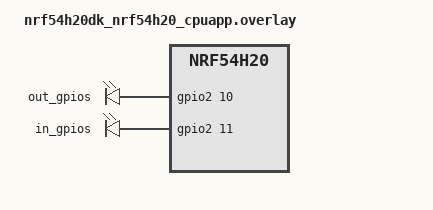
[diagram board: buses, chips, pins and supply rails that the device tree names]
/*
 * Copyright (c) 2025 Nordic Semiconductor ASA
 *
 * SPDX-License-Identifier: LicenseRef-Nordic-5-Clause
 */

/ {
	/* Test requirements:
	 * NFC antenna connected to the DK.
	 */
	test_gpios {
		compatible = "gpio-leds";
		out_gpios: out_gpios {
			gpios = <&gpio2 10 GPIO_ACTIVE_HIGH>;
		};

		in_gpios: in_gpios {
			gpios = <&gpio2 11 GPIO_ACTIVE_HIGH>;
		};
	};
};

&nfct {
	status = "disabled";
	nfct-pins-as-gpios;
};

&gpiote130 {
	status = "okay";
	owned-channels = <7>;
};

&gpio2 {
	status = "okay";
};
